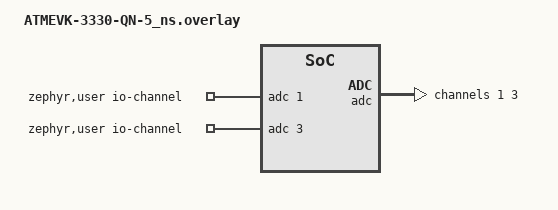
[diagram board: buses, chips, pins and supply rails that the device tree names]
/*
 * Copyright (c) 2023 Atmosic
 *
 * SPDX-License-Identifier: Apache-2.0
 */

/ {
	zephyr,user {
		io-channels = <&adc 1>, <&adc 3>;
	};
};

&adc {
	#address-cells = <1>;
	#size-cells = <0>;

	channel@1 {
		reg = <1>;
		zephyr,gain = "ADC_GAIN_1_4";
		zephyr,reference = "ADC_REF_INTERNAL";
		zephyr,acquisition-time = <ADC_ACQ_TIME_DEFAULT>;
		zephyr,resolution = <11>;
	};

	channel@3 {
		reg = <3>;
		zephyr,gain = "ADC_GAIN_1_2";
		zephyr,reference = "ADC_REF_INTERNAL";
		zephyr,acquisition-time = <ADC_ACQ_TIME_DEFAULT>;
		zephyr,resolution = <11>;
	};
};
